# STM32WB07 register map
File version: 1.0
CPU: CM0+ r0p0, little endian, MPU, no FPU, 2 interrupt priority bits
Registers are 32-bit, read-write, reset 0x0 unless marked. A register's access mark holds for its fields unless they carry their own. Offsets are from the block's base; [hi:lo] are bit positions.

## RCC
Base 0x48400000
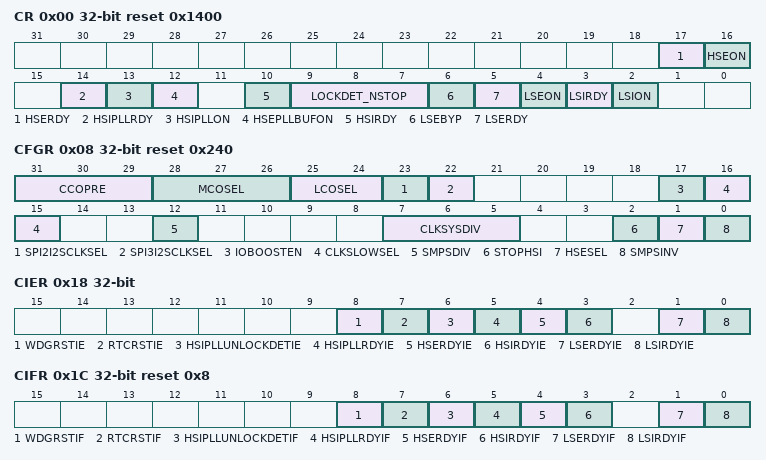
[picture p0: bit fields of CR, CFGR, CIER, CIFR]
0x00 CR reset 0x1400
  [17] HSERDY ro — External High Speed Clock ready flag. Set by hardware to indicate that HSE oscillator is stable.
  [16] HSEON — External High Speed Clock enable. Set and reset by software. in low power mode, HSE is turned off.
  [14] HSIPLLRDY ro — Internal High Speed Clock PLL ready flag.
  [13] HSIPLLON — Internal High Speed Clock PLL enable
  [12] HSEPLLBUFON — External High Speed Clock Buffer for PLL RF2G4 enable. Set and reset by software.
  [10] HSIRDY ro — Internal High Speed clock ready flag. Set by hardware to indicate that internal RC 64MHz oscillator is stable. This bit is activated only if the RC is enabled by HSION (it is not activated if the RC is enabled by an IP request).
  [9:7] LOCKDET_NSTOP — Lock detector Nstop value When start_stop signal is high; a counter is incremented every 16 MHz clock cycle. When the counter reaches (NSTOP+1) x 64 value, the lock_det signal is set high indicating that the PLL is locked. As soon as the start_stop signal is low the counter is reset to 0.
  [6] LSEBYP — External Low Speed Clock bypass. Set and reset by software. Reset source only for this field: PORESETn
  [5] LSERDY ro — External Low Speed Clock ready flag. Set by hardware to indicate that LSE oscillator is stable.
  [4] LSEON — External Low Speed Clock enable. Set and reset by software. Reset source only for this field: PORESETn
  [3] LSIRDY ro — Internal Low Speed oscillator Ready Set and reset by hardware to indicate when the Low Speed Internal RC oscillator is stable. Reset source only for this field: PORESETn
  [2] LSION — Internal Low Speed oscillator enable Set and reset by software. Reset source only for this field: PORESETn
0x08 CFGR reset 0x240
  [31:29] CCOPRE — Configurable Clock Output Prescaler. Set and reset by software. Glitches propagation if CCOPRE is modified after CCO output is enabled. Others: not used
  [28:26] MCOSEL — Main Configurable Clock Output Selection. Set and reset by software. Glitches propagation possible.
  [25:24] LCOSEL — Low speed Configurable Clock Output Selection. Set and reset by software. Glitches propagation possible. Reset source only for this field: PORESETn
  [23] SPI2I2SCLKSEL — Selection of I2S clock: 1x:64MHz peripheral clock
  [22] SPI3I2SCLKSEL — Selection of I2S1 clock: 1x:64MHz peripheral clock
  [17] IOBOOSTEN — IO BOOSTER enable Set and reset by software.
  [16:15] CLKSLOWSEL — slow clock source selection Set by software to select the clock source. This is no glitch free mechanism Reset source only for this field: PORESETn
  [12] SMPSDIV — SMPS clock prescaling factor to generate 4MHz or 8MHz
  [7:5] CLKSYSDIV — CLKSYSDIV: system clock divided factor from HSI_64M.
  [2] STOPHSI — Stop HSI clock source request
  [1] HSESEL — Clock source selection request:
  [0] SMPSINV — bit to control inversion of the SMPS clock
0x18 CIER
  [8] WDGRSTIE — WDGRSTIE: Watchdog reset end Interrupt Enable. Set and reset by software to enable/disable interrupt caused by the watchdog reset end.
  [7] RTCRSTIE — RTCRSTIE: RTC reset end Interrupt Enable. Set and reset by software to enable/disable interrupt caused by the RTC reset end.
  [6] HSIPLLUNLOCKDETIE — HSIPLLUNLOCKDETIE: HSI PLL unlock detection Interrupt Enable. Set and reset by software to enable/disable interrupt caused by the HSI 64MHz PLL unlock.
  [5] HSIPLLRDYIE — HSI PLL Ready Interrupt Enable. Set and reset by software to enable/disable interrupt caused by the HSI 64MHz PLL locked on HSE.
  [4] HSERDYIE — HSE Ready Interrupt Enable Set and reset by software to enable/disable interrupt caused by the external HSE oscillator stabilization.
  [3] HSIRDYIE — HSI Ready Interrupt Enable. Set and reset by software to enable/disable interrupt caused by the internal RC 64MHz oscillator stabilization.
  [1] LSERDYIE — LSE Ready Interrupt Enable. Set and reset by software to enable/disable interrupt caused by the external 32 kHz oscillator stabilization.
  [0] LSIRDYIE — LSI Ready Interrupt Enable. Set and reset by software to enable/disable interrupt caused by internal RC 32 kHz oscillator stabilization.
0x1C CIFR reset 0x8
  [8] WDGRSTIF — WDG reset end Interrupt Flag. Raised when reset is released on 32kHz clock
  [7] RTCRSTIF — RTC reset end Interrupt Flag. Raised when reset is released on 32kHz clock
  [6] HSIPLLUNLOCKDETIF — HSIPLLUNLOCKDETIF: HSI PLL unlock detection Interrupt Flag.
  [5] HSIPLLRDYIF — HSI PLL Ready Interrupt Flag. Set by hardware when HSI PLL 64MHz becomes stable.
  [4] HSERDYIF — HSE Ready Interrupt Flag. Set by hardware when HSE becomes stable.
  [3] HSIRDYIF — HSI Ready Interrupt Flag. Set by hardware when HSI becomes stable.
  [1] LSERDYIF — LSE Ready Interrupt Flag. Set by hardware when LSE clock becomes stable.
  [0] LSIRDYIF — LSI Ready Interrupt flag Set by hardware when LSI clock becomes stable.
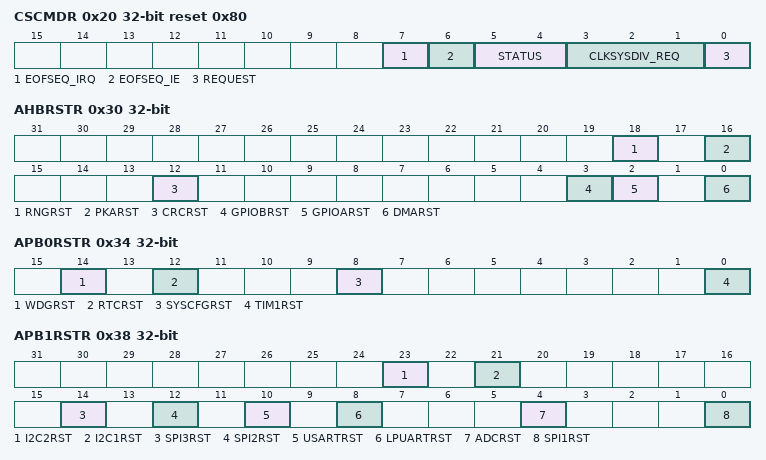
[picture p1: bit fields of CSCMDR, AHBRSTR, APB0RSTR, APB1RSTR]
0x20 CSCMDR reset 0x80
  [7] EOFSEQ_IRQ — End of Sequence flag Set by hardware when clock system swtich is ended
  [6] EOFSEQ_IE — End of sequence Interrupt Enable. Set and reset by software to enable/disable interrupt caused by the clock system switch.
  [5:4] STATUS ro — Status of clock switch sequence
  [3:1] CLKSYSDIV_REQ — system clock dividing factor from HSI_64M requested Note: behavior depends on BLEEN in APB2ENR register
  [0] REQUEST — Request for system clock switching Cleared by hardware when system clock frequency switch is done
0x30 AHBRSTR
  [18] RNGRST — RNG reset Set and reset by software.
  [16] PKARST — PKA reset Set and reset by software.
  [12] CRCRST — CRC reset Set and reset by software.
  [3] GPIOBRST — GPIOB reset Set and reset by software.
  [2] GPIOARST — GPIOA reset Set and reset by software.
  [0] DMARST — DMA and DMAMUX reset Set and reset by software.
0x34 APB0RSTR
  [14] WDGRST — WATCHDOG reset Set and reset by software.
  [12] RTCRST — RTC reset Set and reset by software.
  [8] SYSCFGRST — SYSTEM CONFIG reset Set and reset by software.
  [0] TIM1RST — TIM1: Advanced Timer reset Set and reset by software.
0x38 APB1RSTR
  [23] I2C2RST — 2C2 reset.
  [21] I2C1RST — I2C1 reset Set and reset by software.
  [14] SPI3RST — SPI3 reset Set and reset by software.
  [12] SPI2RST — SPI2 reset.
  [10] USARTRST — USART reset Set and reset by software.
  [8] LPUARTRST — LPUART reset Set and reset by software.
  [4] ADCRST — ADC reset.
  [0] SPI1RST — SPI1 reset
0x40 APB2RSTR
  [0] MRBLERST — MR_BLE (Bluetooth radio) reset.
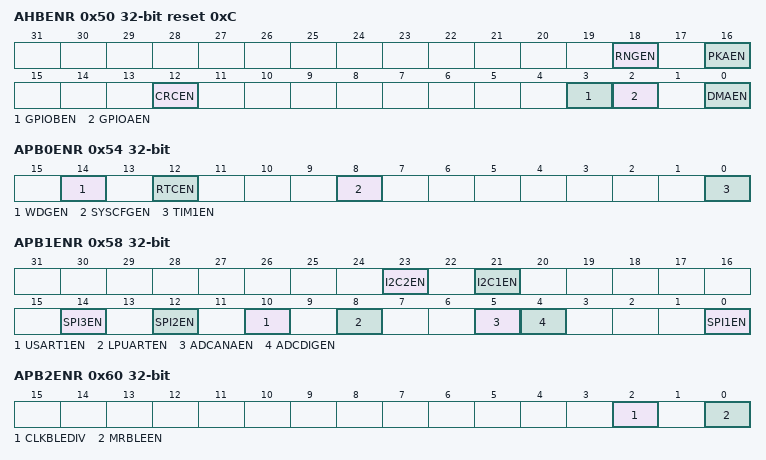
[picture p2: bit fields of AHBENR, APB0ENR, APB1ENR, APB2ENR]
0x50 AHBENR reset 0xC
  [18] RNGEN — RNG clock enable Set and enable by software.
  [16] PKAEN — PKA clock enable Set and enable by software.
  [12] CRCEN — CRC enable Set and enable by software.
  [3] GPIOBEN — GPIOB enable. It must be enabled by default
  [2] GPIOAEN — GPIOA enable. It must be enabled by default
  [0] DMAEN — DMA and DMAMUX enable Set and enable by software.
0x54 APB0ENR
  [14] WDGEN — Watchdog clock enable. Set and enable by software.
  [12] RTCEN — RTC clock enable Set and enable by software. Reset source only for this field: PORESETn
  [8] SYSCFGEN — SYSTEM CONFIG enable Set and enable by software.
  [0] TIM1EN — TIM1 enable
0x58 APB1ENR
  [23] I2C2EN — I2C2 enable.
  [21] I2C1EN — I2C1 clock enable Set and enable by software.
  [14] SPI3EN — SPI3 clock enable Set and enable by software.
  [12] SPI2EN — SPI2 enable
  [10] USART1EN — USART clock enable Set and enable by software.
  [8] LPUARTEN — LPUART clock enable Set and enable by software.
  [5] ADCANAEN — ADC clock enable for the analog part of the ADC block.
  [4] ADCDIGEN — ADC clock enable for digital part of the ADC block.
  [0] SPI1EN — SPI1 enable.
0x60 APB2ENR
  [2] CLKBLEDIV — MR_BLE clock frequency selection when RCC_APB2ENR.MRBLEEN=1
  [0] MRBLEEN — MR_BLE enable
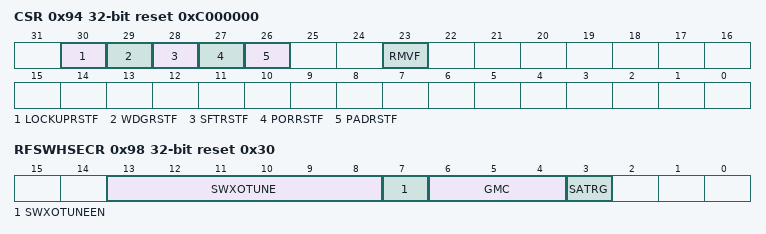
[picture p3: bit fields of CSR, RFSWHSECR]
0x94 CSR reset 0xC000000
  [30] LOCKUPRSTF ro — LOCK UP reset flag from CM0 Reset by software by writing the RMVF bit. Set by hardware from unrecoverable exception CPU. It reset V12i domain, FLASH controller and peripherals.
  [29] WDGRSTF ro — Watchdog reset flag Reset by software by writing the RMVF bit. Set by hardware when a watchdog reset from V33 domain occurs.
  [28] SFTRSTF ro — Software reset flag Reset by software by writing the RMVF bit. Set by hardware when a software reset occurs.
  [27] PORRSTF ro — POWER reset flag Reset by software by writing the RMVF bit. Set by hardware when a power reset occurs from LPMURESET block.
  [26] PADRSTF ro — SYSTEM reset flag Reset by software by writing the RMVF bit. Set by hardware when a reset from pad occurs.
  [23] RMVF wo — Remove reset flag Set by software to clear the value of the reset flags. It auto clears by HW after clearing reason flags
0x98 RFSWHSECR reset 0x30
  [13:8] SWXOTUNE — RF-HSE capacitor bank tuning value by SW Set by software
  [7] SWXOTUNEEN — RF-HSE capacitor bank tuning by SW enable Set by software
  [6:4] GMC — High Speed External XO current control Set by software.
  [3] SATRG — Sense Amplifier threshold Set by software.
0x9C RFHSECR ro
  [5:0] XOTUNE — RF-HSE capacitor bank tuning Set by option byte loading soon after Power On Reset.
